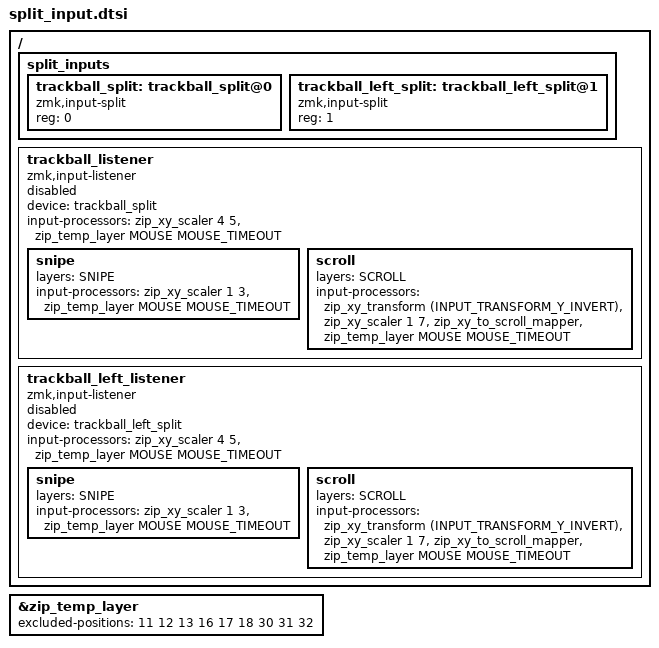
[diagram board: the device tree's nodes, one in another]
#include <dt-bindings/zmk/input_transform.h>
#include <input/processors.dtsi>

#include "../../../config/layers.h"

// How long (ms) MOUSE stays active after the ball last moved
#define MOUSE_TIMEOUT 800

// Keys that keep MOUSE active instead of dropping back to BASE:
// left home row clicks (11 12 13), right home row (16 17 18), left thumbs (30 31 32)
&zip_temp_layer {
  excluded-positions = <11 12 13 16 17 18 30 31 32>;
};

/ {
  split_inputs {
    #address-cells = <1>;
    #size-cells = <0>;

    trackball_split: trackball_split@0 {
      compatible = "zmk,input-split";
      reg = <0>;
    };

    trackball_left_split: trackball_left_split@1 {
      compatible = "zmk,input-split";
      reg = <1>;
    };
  };

  trackball_listener: trackball_listener {
    compatible = "zmk,input-listener";
    status = "disabled";
    device = <&trackball_split>;

    input-processors = <&zip_xy_scaler 4 5>, <&zip_temp_layer MOUSE MOUSE_TIMEOUT>;

    snipe {
      layers = <SNIPE>;
      input-processors = <&zip_xy_scaler 1 3>, <&zip_temp_layer MOUSE MOUSE_TIMEOUT>;
    };

    scroll {
      layers = <SCROLL>;
      input-processors = <&zip_xy_transform (INPUT_TRANSFORM_Y_INVERT)>, <&zip_xy_scaler 1 7>, <&zip_xy_to_scroll_mapper>, <&zip_temp_layer MOUSE MOUSE_TIMEOUT>;
    };
  };

  trackball_left_listener: trackball_left_listener {
    compatible = "zmk,input-listener";
    status = "disabled";
    device = <&trackball_left_split>;

    input-processors = <&zip_xy_scaler 4 5>, <&zip_temp_layer MOUSE MOUSE_TIMEOUT>;

    snipe {
      layers = <SNIPE>;
      input-processors = <&zip_xy_scaler 1 3>, <&zip_temp_layer MOUSE MOUSE_TIMEOUT>;
    };

    scroll {
      layers = <SCROLL>;
      input-processors = <&zip_xy_transform (INPUT_TRANSFORM_Y_INVERT)>, <&zip_xy_scaler 1 7>, <&zip_xy_to_scroll_mapper>, <&zip_temp_layer MOUSE MOUSE_TIMEOUT>;
    };
  };
};
